# STM32H562 register map
File version: 1.7
CPU: CM33 r0p0, little endian, MPU, FPU, 4 interrupt priority bits
Registers are 32-bit, read-write, reset 0x0 unless marked. A register's access mark holds for its fields unless they carry their own. Offsets are from the block's base; [hi:lo] are bit positions; {n}, {i} and the like mark numbered series.

## RNG — True random number generator
Base 0x420C0800
Same registers: SEC_RNG 0x520C0800
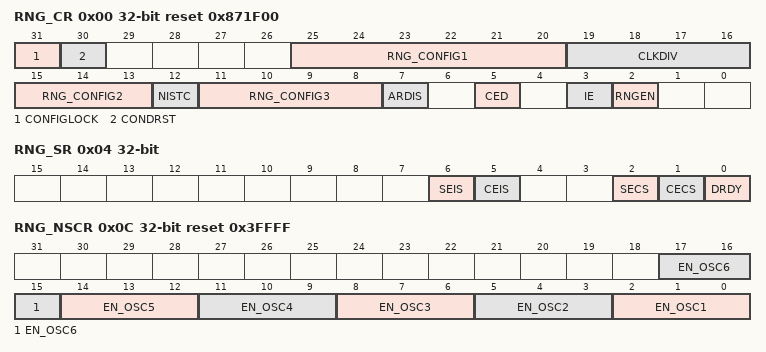
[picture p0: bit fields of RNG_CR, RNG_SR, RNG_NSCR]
0x00 RNG_CR reset 0x871F00 — RNG control register
  [31] CONFIGLOCK — RNG Config Lock This bitfield is set once: if this bit is set it can only be reset to 0 if RNG is reset.
    0=Writes to the RNG_CR configuration bits [29:4] are allowed; 1=Writes to the RNG_CR configuration bits [29:4] are ignored until the next RNG reset
  [30] CONDRST — Conditioning soft reset Write 1 and then write 0 to reset the conditioning logic, clear all the FIFOs and start a new RNG initialization process, with RNG_SR cleared. Registers RNG_CR and RNG_NSCR are not changed by CONDRST. This bit must be set to 1 in the same access that set any configuration bits [29:4]. In other words, when CONDRST bit is set to 1 correct configuration in bits [29:4] must also be written. When CONDRST is set to 0 by software its value goes to 0 when the reset process is done. It takes about 2 AHB clock cycles + 2 RNG clock cycles.
  [25:20] RNG_CONFIG1 — RNG configuration 1 Reserved to the RNG configuration (bitfield 1). Must be initialized using the recommended value documented in . Writing any bit of RNG_CONFIG1 is taken into account only if CONDRST bit is set to 1 in the same access, while CONFIGLOCK remains at 0. Writing to this bit is ignored if CONFIGLOCK=1.
  [19:16] CLKDIV — Clock divider factor This value used to configure an internal programmable divider (from 1 to 16) acting on the incoming RNG clock. These bits can be written only when the core is disabled (RNGEN=0). ... Writing these bits is taken into account only if CONDRST bit is set to 1 in the same access, while CONFIGLOCK remains at 0. Writing to this bit is ignored if CONFIGLOCK=1.
    0=internal RNG clock after divider is similar to incoming RNG clock; 1=two RNG clock cycles per internal RNG clock; 15=215 RNG clock cycles per internal clock, e.g. an incoming 48MHz RNG clock becomes a 1.5 kHz internal RNG clock.
  [15:13] RNG_CONFIG2 — RNG configuration 2 Reserved to the RNG configuration (bitfield 2). Refer to RNG_CONFIG1 bitfield for details.
  [12] NISTC — Non NIST compliant four conditioning loops are performed and 512 bits of noise source are used. Writing this bit is taken into account only if CONDRST bit is set to 1 in the same access, while CONFIGLOCK remains at 0. Writing to this bit is ignored if CONFIGLOCK=1.
    0=Hardware default values for NIST compliant RNG. In this configuration per 128-bit output; 1=Custom values for NIST compliant RNG. See Section 38.6: RNG entropy source validation for proposed configuration.
  [11:8] RNG_CONFIG3 — RNG configuration 3 Reserved to the RNG configuration (bitfield 3). Refer to RNG_CONFIG1 bitfield for details. If NISTC bit is cleared in this register RNG_CONFIG3 bitfield values are ignored by RNG.
  [7] ARDIS — Auto reset disable When auto-reset is enabled application still need to clear SEIS bit after a noise source error. Writing this bit is taken into account only if CONDRST bit is set to 1 in the same access, while CONFIGLOCK remains at 0. Writing to this bit is ignored if CONFIGLOCK=1.
    0=When a noise source error occurs RNG performs an automatic reset to clear SECS bit; 1=When a noise source error occurs application must reset RNG by writing CONDRST to 1 then to 0, in order to restart random number generation
  [5] CED — Clock error detection The clock error detection cannot be enabled nor disabled on-the-fly when the RNG is enabled, i.e. to enable or disable CED the RNG must be disabled. Writing this bit is taken into account only if CONDRST bit is set to 1 in the same access, while CONFIGLOCK remains at 0. Writing to this bit is ignored if CONFIGLOCK=1.
    0=Clock error detection is enable; 1=Clock error detection is disable
  [3] IE — Interrupt Enable
    0=RNG Interrupt is disabled; 1=RNG Interrupt is enabled. An interrupt is pending as soon as DRDY='1', SEIS='1' or CEIS=1 in the RNG_SR register.
  [2] RNGEN — True random number generator enable
    0=True random number generator is disabled. Analog noise sources are powered off and logic clocked by the RNG clock is gated.; 1=True random number generator is enabled
0x04 RNG_SR access per field — RNG status register
  [6] SEIS rw — Seed error interrupt status This bit is set at the same time as SECS. It is cleared by writing 0 (unless CONDRST is used). Writing 1 has no effect. An interrupt is pending if IE = 1 in the RNG_CR register.
    0=No faulty sequence detected; 1=At least one faulty sequence is detected. See SECS bit description for details.
  [5] CEIS rw — Clock error interrupt status This bit is set at the same time as CECS. It is cleared by writing 0. Writing 1 has no effect. An interrupt is pending if IE = 1 in the RNG_CR register.
    0=The RNG clock is correct (fRNGCLK fHCLK/32); 1=The RNG clock before internal divider is detected too slow (fRNGCLK fHCLK/32)
  [2] SECS ro — Seed error current status Run-time repetition count test failed (noise source has provided more than 24 consecutive bits at a constant value 0' or 1', or more than 32 consecutive occurrence of two bits patterns 01' or 10') Start-up or continuous adaptive proportion test on noise source failed. Start-up post-processing/conditioning sanity check failed.
    0=No faulty sequence has currently been detected. If the SEIS bit is set, this means that a faulty sequence was detected and the situation has been recovered.; 1=At least one of the following faulty sequence has been detected:
  [1] CECS ro — Clock error current status Note: CECS bit is valid only if the CED bit in the RNG_CR register is set to 0.
    0=The RNG clock is correct (fRNGCLK fHCLK/32). If the CEIS bit is set, this means that a slow clock was detected and the situation has been recovered.; 1=The RNG clock is too slow (fRNGCLK fHCLK/32)
  [0] DRDY ro — Data Ready Once the output buffer becomes empty (after reading the RNG_DR register), this bit returns to 0 until a new random value is generated. Note: The DRDY bit can rise when the peripheral is disabled (RNGEN=0 in the RNG_CR register). If IE=1 in the RNG_CR register, an interrupt is generated when DRDY=1.
    0=The RNG_DR register is not yet valid, no random data is available; 1=The RNG_DR register contains valid random data
0x08 RNG_DR ro — RNG data register
  [31:0] RNDATA — Random data 32-bit random data which are valid when DRDY=1. When DRDY=0 RNDATA value is zero. It is recommended to always verify that RNG_DR is different from zero. Because when it is the case a seed error occurred between RNG_SR polling and RND_DR output reading (rare event).
0x0C RNG_NSCR reset 0x3FFFF — RNG noise source control register
  [3n-1:3n-3] EN_OSC{n} (n=1..6) — When the RNG is enabled (RNGEN bit set), each bit of this bitfield enables one of the three inputs from the oscillator instance number {n}.
0x10 RNG_HTCR reset 0x72AC — RNG health test control register
  [31:0] HTCFG — health test configuration This configuration is used by RNG to configure the health tests. See entropy source validation for the recommended value. Note: The RNG behavior, including the read to this register, is not guaranteed if a different value from the recommended value is written.
